# STM32L442 register map
File version: 1.0
CPU: CM4 r0p1, little endian, MPU, FPU, 4 interrupt priority bits
Registers are 32-bit, read-write, reset 0x0 unless marked. A register's access mark holds for its fields unless they carry their own. Offsets are from the block's base; [hi:lo] are bit positions.

## ADC123_Common — Analog-to-Digital Converter
Base 0x50040300
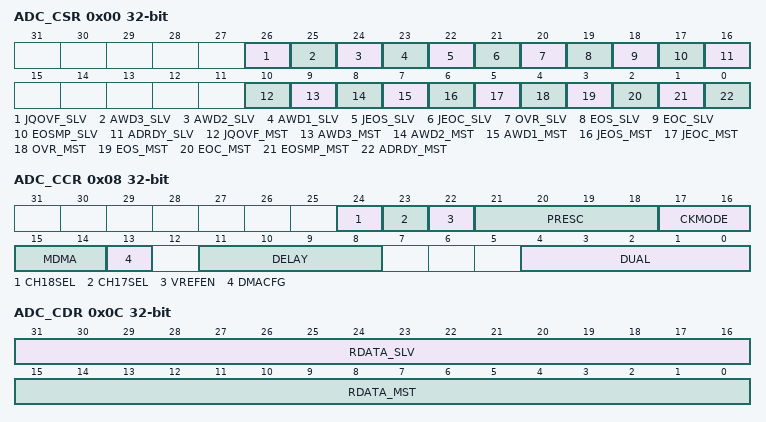
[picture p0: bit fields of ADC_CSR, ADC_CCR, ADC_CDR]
0x00 ADC_CSR ro — ADC common status register
  [26] JQOVF_SLV — Injected Context Queue Overflow flag of the slave ADC This bit is a copy of the JQOVF bit in the corresponding ADC_ISR register.
  [25] AWD3_SLV — Analog watchdog 3 flag of the slave ADC This bit is a copy of the AWD3 bit in the corresponding ADC_ISR register.
  [24] AWD2_SLV — Analog watchdog 2 flag of the slave ADC This bit is a copy of the AWD2 bit in the corresponding ADC_ISR register.
  [23] AWD1_SLV — Analog watchdog 1 flag of the slave ADC This bit is a copy of the AWD1 bit in the corresponding ADC_ISR register.
  [22] JEOS_SLV — End of injected sequence flag of the slave ADC This bit is a copy of the JEOS bit in the corresponding ADC_ISR register.
  [21] JEOC_SLV — End of injected conversion flag of the slave ADC This bit is a copy of the JEOC bit in the corresponding ADC_ISR register.
  [20] OVR_SLV — Overrun flag of the slave ADC This bit is a copy of the OVR bit in the corresponding ADC_ISR register.
  [19] EOS_SLV — End of regular sequence flag of the slave ADC. This bit is a copy of the EOS bit in the corresponding ADC_ISR register.
  [18] EOC_SLV — End of regular conversion of the slave ADC This bit is a copy of the EOC bit in the corresponding ADC_ISR register.
  [17] EOSMP_SLV — End of Sampling phase flag of the slave ADC This bit is a copy of the EOSMP2 bit in the corresponding ADC_ISR register.
  [16] ADRDY_SLV — Slave ADC ready This bit is a copy of the ADRDY bit in the corresponding ADC_ISR register.
  [10] JQOVF_MST — Injected Context Queue Overflow flag of the master ADC This bit is a copy of the JQOVF bit in the corresponding ADC_ISR register.
  [9] AWD3_MST — Analog watchdog 3 flag of the master ADC This bit is a copy of the AWD3 bit in the corresponding ADC_ISR register.
  [8] AWD2_MST — Analog watchdog 2 flag of the master ADC This bit is a copy of the AWD2 bit in the corresponding ADC_ISR register.
  [7] AWD1_MST — Analog watchdog 1 flag of the master ADC This bit is a copy of the AWD1 bit in the corresponding ADC_ISR register.
  [6] JEOS_MST — End of injected sequence flag of the master ADC This bit is a copy of the JEOS bit in the corresponding ADC_ISR register.
  [5] JEOC_MST — End of injected conversion flag of the master ADC This bit is a copy of the JEOC bit in the corresponding ADC_ISR register.
  [4] OVR_MST — Overrun flag of the master ADC This bit is a copy of the OVR bit in the corresponding ADC_ISR register.
  [3] EOS_MST — End of regular sequence flag of the master ADC This bit is a copy of the EOS bit in the corresponding ADC_ISR register.
  [2] EOC_MST — End of regular conversion of the master ADC This bit is a copy of the EOC bit in the corresponding ADC_ISR register.
  [1] EOSMP_MST — End of Sampling phase flag of the master ADC This bit is a copy of the EOSMP bit in the corresponding ADC_ISR register.
  [0] ADRDY_MST — Master ADC ready This bit is a copy of the ADRDY bit in the corresponding ADC_ISR register.
0x08 ADC_CCR — ADC common control register
  [24] CH18SEL — CH18 selection This bit is set and cleared by software to control channel 18.
    0=V<sub>BAT</sub> channel disabled, dac_out2 selected; 1=V<sub>BAT</sub> channel enabled
  [23] CH17SEL — CH17 selection This bit is set and cleared by software to control channel 17.
    0=Temperature sensor channel disabled, dac_out1 selected; 1=Temperature sensor channel enabled
  [22] VREFEN — V<sub>REFINT</sub> enable This bit is set and cleared by software to enable/disable the V<sub>REFINT</sub> channel.
    0=V<sub>REFINT</sub> channel disabled; 1=V<sub>REFINT</sub> channel enabled
  [21:18] PRESC — ADC prescaler These bits are set and cleared by software to select the frequency of the clock to the ADC. The clock is common for all the ADCs. other: reserved Note: The software is allowed to write these bits only when the ADC is disabled (ADCAL = 0, JADSTART = 0, ADSTART = 0, ADSTP = 0, ADDIS = 0 and ADEN = 0). The ADC prescaler value is applied only when CKMODE[1:0] = 00.
    0=input ADC clock not divided; 1=input ADC clock divided by 2; 2=input ADC clock divided by 4; 3=input ADC clock divided by 6; 4=input ADC clock divided by 8; 5=input ADC clock divided by 10; 6=input ADC clock divided by 12; 7=input ADC clock divided by 16; 8=input ADC clock divided by 32; 9=input ADC clock divided by 64; 10=input ADC clock divided by 128; 11=input ADC clock divided by 256
  [17:16] CKMODE — ADC clock mode These bits are set and cleared by software to define the ADC clock scheme (which is common to both master and slave ADCs): In all synchronous clock modes, there is no jitter in the delay from a timer trigger to the start of a conversion. Note: The software is allowed to write these bits only when the ADCs are disabled (ADCAL = 0, JADSTART = 0, ADSTART = 0, ADSTP = 0, ADDIS = 0 and ADEN = 0).
    0=CK_ADCx (x = 123) (Asynchronous clock mode), generated at product level (refer to Section 6: Reset and clock control (RCC)); 1=HCLK/1 (Synchronous clock mode). This configuration must be enabled only if the AHB clock prescaler is set (HPRE[3:0] = 0xxx in RCC_CFGR register) and if the system clock has a 50% duty cycle.; 2=HCLK/2 (Synchronous clock mode); 3=HCLK/4 (Synchronous clock mode)
  [15:14] MDMA — Direct memory access mode for dual ADC mode This bitfield is set and cleared by software. Refer to the DMA controller section for more details. Note: The software is allowed to write these bits only when ADSTART = 0 (which ensures that no regular conversion is ongoing).
    0=MDMA mode disabled; 1=Enable dual interleaved mode to output to the master channel of DFSDM interface both Master and the Slave result (16-bit data width); 2=MDMA mode enabled for 12 and 10-bit resolution; 3=MDMA mode enabled for 8 and 6-bit resolution
  [13] DMACFG — DMA configuration (for dual ADC mode) This bit is set and cleared by software to select between two DMA modes of operation and is effective only when DMAEN = 1. For more details, refer to Section : Managing conversions using the DMA Note: The software is allowed to write these bits only when ADSTART = 0 (which ensures that no regular conversion is ongoing).
    0=DMA One Shot mode selected; 1=DMA Circular mode selected
  [11:8] DELAY — Delay between 2 sampling phases These bits are set and cleared by software. These bits are used in dual interleaved modes. Refer to Table 112 for the value of ADC resolution versus DELAY bits values. Note: The software is allowed to write these bits only when the ADCs are disabled (ADCAL = 0, JADSTART = 0, ADSTART = 0, ADSTP = 0, ADDIS = 0 and ADEN = 0).
  [4:0] DUAL — Dual ADC mode selection These bits are written by software to select the operating mode. All the ADCs independent: 00001 to 01001: Dual mode, master and slave ADCs working together All other combinations are reserved and must not be programmed Note: The software is allowed to write these bits only when the ADCs are disabled (ADCAL = 0, JADSTART = 0, ADSTART = 0, ADSTP = 0, ADDIS = 0 and ADEN = 0).
    0=Independent mode; 1=Combined regular simultaneous + injected simultaneous mode; 2=Combined regular simultaneous + alternate trigger mode; 3=Combined Interleaved mode + injected simultaneous mode; 5=Injected simultaneous mode only; 6=Regular simultaneous mode only; 7=Interleaved mode only; 9=Alternate trigger mode only
0x0C ADC_CDR ro — ADC common regular data register for dual mode
  [31:16] RDATA_SLV — Regular data of the slave ADC In dual mode, these bits contain the regular data of the slave ADC. Refer to Section 16.4.32: Dual ADC modes. The data alignment is applied as described in Section : Data register, data alignment and offset (ADC_DR, OFFSETy, OFFSETy_CH, ALIGN))
  [15:0] RDATA_MST — Regular data of the master ADC. In dual mode, these bits contain the regular data of the master ADC. Refer to Section 16.4.32: Dual ADC modes. The data alignment is applied as described in Section : Data register, data alignment and offset (ADC_DR, OFFSETy, OFFSETy_CH, ALIGN)) In MDMA = 11 mode, bits 15:8 contains SLV_ADC_DR[7:0], bits 7:0 contains MST_ADC_DR[7:0].

## Notices in the file
Copyright (c) 2024 STMicroelectronics.
SPDX-License-Identifier: Apache-2.0
Licensed under the Apache License, Version 2.0 (the "License");
you may not use this file except in compliance with the License.
You may obtain a copy of the License at
http://www.apache.org/licenses/LICENSE-2.0
Unless required by applicable law or agreed to in writing, software
distributed under the License is distributed on an "AS IS" BASIS,
WITHOUT WARRANTIES OR CONDITIONS OF ANY KIND, either express or implied.
See the License for the specific language governing permissions and
limitations under the License.
